# STM32U073 register map
File version: 1.0
CPU: CM0+ r0p1, little endian, MPU, no FPU, 4 interrupt priority bits
Registers are 32-bit, read-write, reset 0x0 unless marked. A register's access mark holds for its fields unless they carry their own. Offsets are from the block's base; [hi:lo] are bit positions; {n}, {i} and the like mark numbered series.

## CRC — CRC address block description
Base 0x40023000
0x00 DR reset 0xFFFFFFFF — CRC data register
  [31:0] DR — Data register bits This register is used to write new data to the CRC calculator. It holds the previous CRC calculation result when it is read. If the data size is less than 32 bits, the least significant bits are used to write/read the correct value.
0x00 DR8 8-bit reset 0xFF (alternate view of DR) — Data register - byte sized
  [7:0] DR8 — Data register bits
0x00 DR16 16-bit reset 0xFFFF (alternate view of DR) — Data register - half-word sized
  [15:0] DR16 — Data register bits
0x04 IDR — CRC independent data register
  [31:0] IDR — General-purpose 32-bit data register bits These bits can be used as a temporary storage location for four bytes. This register is not affected by CRC resets generated by the RESET bit in the CRC_CR register
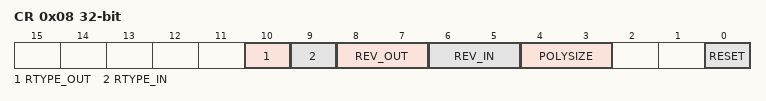
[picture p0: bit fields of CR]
0x08 CR — CRC control register
  [10] RTYPE_OUT — Reverse type output This bit controls the reversal granularity of the output data.
  [9] RTYPE_IN — Reverse type input This bit controls the reversal granularity of the input data.
  [8:7] REV_OUT — Reverse output data This bitfield controls the reversal of the bit order of the output data.
    0=Normal (Bit order not affected); 1=Reversed (Bit reversed output)
  [6:5] REV_IN — Reverse input data This bitfield controls the reversal of the bit order of the input data
    0=Normal (Bit order not affected); 1=Byte (Bit reversal done by byte); 2=HalfWord (Bit reversal done by half-word); 3=Word (Bit reversal done by word)
  [4:3] POLYSIZE — Polynomial size These bits control the size of the polynomial.
    0=32-bit polynomial; 1=16-bit polynomial; 2=8-bit polynomial; 3=7-bit polynomial
  [0] RESET — RESET bit This bit is set by software to reset the CRC calculation unit and set the data register to the value stored in the CRC_INIT register. This bit can only be set, it is automatically cleared by hardware
    on write: 1=Resets the CRC calculation unit and sets the data register to 0xFFFF FFFF
0x10 INIT reset 0xFFFFFFFF — CRC initial value
  [31:0] INIT — Programmable initial CRC value This register is used to write the CRC initial value.
0x14 POL reset 0x4C11DB7 — CRC polynomial
  [31:0] POL — Programmable polynomial This register is used to write the coefficients of the polynomial to be used for CRC calculation. If the polynomial size is less than 32 bits, the least significant bits have to be used to program the correct value.

## DMAMUX — DMAMUX address block description
Base 0x40020800
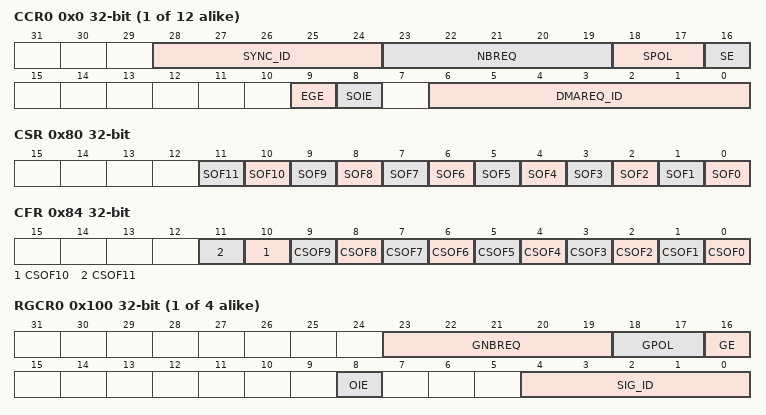
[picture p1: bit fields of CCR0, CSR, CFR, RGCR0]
{0x0+4i} CCR{i} (i=0..11) — DMA Multiplexer Channel {i} Control register
  [28:24] SYNC_ID — Synchronization identification Selects the synchronization input (see Table137: DMAMUX: assignment of synchronization inputs to resources).
  [23:19] NBREQ — Number of DMA requests minus 1 to forward Defines the number of DMA requests to forward to the DMA controller after a synchronization event, and/or the number of DMA requests before an output event is generated. This field must only be written when both SE and EGE bits are low.
  [18:17] SPOL — Synchronization polarity Defines the edge polarity of the selected synchronization input:
    0=NoEdge (No event, i.e. no synchronization nor detection); 1=RisingEdge; 2=FallingEdge; 3=BothEdges (Rising and falling edges)
  [16] SE — Synchronization enable
    0=Disabled (Synchronization disabled); 1=Enabled (Synchronization enabled)
  [9] EGE — Event generation enable
    0=Disabled (Event generation disabled); 1=Enabled (Event generation enabled)
  [8] SOIE — Synchronization overrun interrupt enable
    0=Disabled (Synchronization overrun interrupt disabled); 1=Enabled (Synchronization overrun interrupt enabled)
  [6:0] DMAREQ_ID — DMA request identification Selects the input DMA request. See the DMAMUX table about assignments of multiplexer inputs to resources.
0x80 CSR ro — DMAMUX request line multiplexer interrupt channel status register
  [n] SOF{n} (n=0..11) — Synchronization Overrun Flag {n}
    0=NoSyncEvent (No synchronization event occured on a DMA request line multiplexer channel x, while the DMA request counter value is lower than NBREQ); 1=SyncEvent (Synchronization event occured on a DMA request line multiplexer channel x, while the DMA request counter value is lower than NBREQ)
0x84 CFR wo — DMAMUX request line multiplexer interrupt clear flag register
  [n] CSOF{n} (n=0..11) write-1-clears — Synchronization Clear Overrun Flag {n}
    1=Clear synchronization flag
{0x100+4i} RGCR{i} (i=0..3) — DMAMUX request generator channel {i} configuration register
  [23:19] GNBREQ — Number of DMA requests to be generated (minus 1) Defines the number of DMA requests to be generated after a trigger event. The actual number of generated DMA requests is GNBREQ +1. Note: This field must be written only when GE bit is disabled.
  [18:17] GPOL — DMA request generator trigger polarity Defines the edge polarity of the selected trigger input
    0=NoEdge (No event, i.e. no detection nor generation); 1=RisingEdge; 2=FallingEdge; 3=BothEdges (Rising and falling edges)
  [16] GE — DMA request generator channel x enable
    0=Disabled (DMA request generation disabled); 1=Enabled (DMA request enabled)
  [8] OIE — Trigger overrun interrupt enable
    0=Disabled (Trigger overrun interrupt disabled); 1=Enabled (Trigger overrun interrupt enabled)
  [4:0] SIG_ID — Signal identification Selects the DMA request trigger input used for the channel x of the DMA request generator
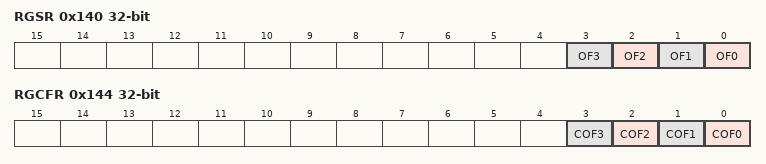
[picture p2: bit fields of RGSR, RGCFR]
0x140 RGSR ro — DMAMUX request generator interrupt status register
  [n] OF{n} (n=0..3) — Generator Overrun Flag {n}
    0=NoTrigger (No new trigger event occured on DMA request generator channel x, before the request counter underrun); 1=Trigger (New trigger event occured on DMA request generator channel x, before the request counter underrun)
0x144 RGCFR wo — DMAMUX request generator interrupt clear flag register
  [n] COF{n} (n=0..3) write-1-clears — Generator Clear Overrun Flag {n}
    1=Clear overrun flag
